# M4G8 register map
File version: 0.1
Registers are 32-bit, read-write, reset 0x0 unless marked. A register's access mark holds for its fields unless they carry their own. Offsets are from the block's base; [hi:lo] are bit positions; {n}, {i} and the like mark numbered series.

## RTC — Real Time Clock (RTC)
Base 0x400E4800
0x00 SECR 8-bit (reset mask 0x80) — RTC Sec setting register
  [6:0] SE
0x01 MINR 8-bit (reset mask 0x80) — RTC Min settging register
  [6:0] MI
0x02 HOURR 8-bit (reset mask 0xC0) — RTC Hour setting register
  [5:0] HO
0x04 DAYR 8-bit (reset mask 0xF8) — RTC Day setting register
  [2:0] WE
0x05 DATER 8-bit (reset mask 0xC0) — RTC Date setting register
  [5:0] DA
0x06 MONTHR_A 8-bit (reset mask 0xE0) — RTC Month settging register PAGE0
  [4:0] MO
0x06 MONTHR_B 8-bit (reset mask 0xFE) (RTC_MONTHR view) — RTC Month settging register PAGE0
  [0] MO0
0x07 YEARR_A 8-bit reset not defined — RTC Year setting register PAGE0
  [7:0] YE
0x07 YEARR_B 8-bit (reset mask 0xFC) (RTC_YEARR view) — RTC Leap year register PAGE1
  [1:0] LEAP
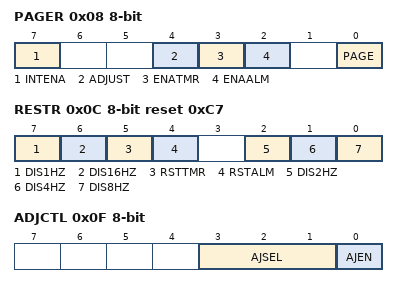
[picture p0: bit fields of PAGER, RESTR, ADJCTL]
0x08 PAGER 8-bit (reset mask 0xF3) — RTC Page register
  [7] INTENA, [4] ADJUST, [3] ENATMR, [2] ENAALM, [0] PAGE
0x0C RESTR 8-bit reset 0xC7 — RTC Reset register
  [7] DIS1HZ, [6] DIS16HZ, [5] RSTTMR, [4] RSTALM, [2] DIS2HZ, [1] DIS4HZ, [0] DIS8HZ
0x0E PROTECT 8-bit reset 0xC1 — RTC clock adjust control register
0x0F ADJCTL 8-bit — RTC protect register
  [3:1] AJSEL, [0] AJEN
0x10 ADJDAT 8-bit reset not defined — RTC clock adjust data register
0x11 ADJSIGN 8-bit (reset mask 0xFE)
  [0] ADJSIGN

## CEC — Consumer Electronics Control (CEC)
Base 0x400E8000
0x00 EN — CEC Enable Register
  [0] CECEN
0x04 ADD — CEC Logical Address Register
  [15:0] CECADD
0x08 RESET wo — CEC Software Reset Register
  [0] CECRESET
0x0C REN (reset mask 0xFFFFFFFE) — CEC Receive Enable Register
  [0] CECREN
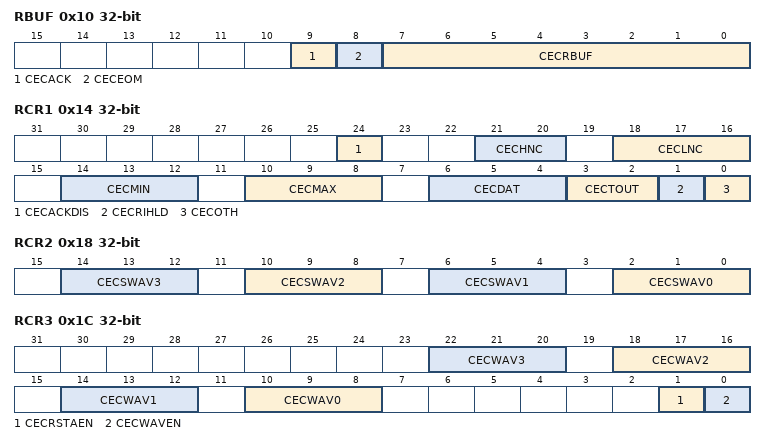
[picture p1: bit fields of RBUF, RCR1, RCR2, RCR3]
0x10 RBUF ro — CEC Receive Buffer Register
  [9] CECACK, [8] CECEOM, [7:0] CECRBUF
0x14 RCR1 — CEC Receive Control Register 1
  [24] CECACKDIS, [21:20] CECHNC, [18:16] CECLNC, [14:12] CECMIN, [10:8] CECMAX, [6:4] CECDAT, [3:2] CECTOUT, [1] CECRIHLD, [0] CECOTH
0x18 RCR2 — CEC Receive Control Register 2
  [4n+2:4n] CECSWAV{n} (n=0..3)
0x1C RCR3 — CEC Receive Control Register 3
  [4n+10:4n+8] CECWAV{n} (n=0..3), [1] CECRSTAEN, [0] CECWAVEN
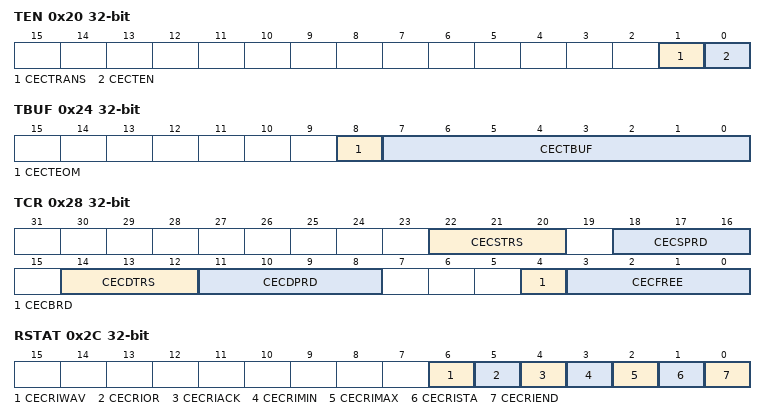
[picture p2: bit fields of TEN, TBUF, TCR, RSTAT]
0x20 TEN (reset mask 0xFFFFFFFE) — CEC Transmit Enable Register
  [1] CECTRANS ro, [0] CECTEN wo
0x24 TBUF — CEC Transmit Buffer Register
  [8] CECTEOM, [7:0] CECTBUF
0x28 TCR — CEC Transmit Control Register
  [22:20] CECSTRS, [18:16] CECSPRD, [14:12] CECDTRS, [11:8] CECDPRD, [4] CECBRD, [3:0] CECFREE
0x2C RSTAT ro — CEC Receive Interrupt Status Register
  [6] CECRIWAV, [5] CECRIOR, [4] CECRIACK, [3] CECRIMIN, [2] CECRIMAX, [1] CECRISTA, [0] CECRIEND
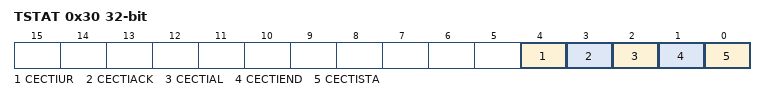
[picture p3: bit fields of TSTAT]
0x30 TSTAT ro — CEC Transmit Interrupt Status Register
  [4] CECTIUR, [3] CECTIACK, [2] CECTIAL, [1] CECTIEND, [0] CECTISTA
0x34 FSSEL — CEC sampling clock selection Register
  [0] CECCLK

## RMC — Remote Control Signal Preprocessor (RMC)
Base 0x400E8100
0x00 EN — RMC Enable Register
  [0] RMCEN
0x04 REN — RMC Receive Enable Register
  [0] RMCREN
0x08 RBUF1 ro — RMC Receive Data Buffer Register 1
  [31:0] RMCRBUF
0x0C RBUF2 ro — RMC Receive Data Buffer Register 2
  [31:0] RMCRBUF
0x10 RBUF3 ro — RMC Receive Data Buffer Register 3
  [7:0] RMCRBUF
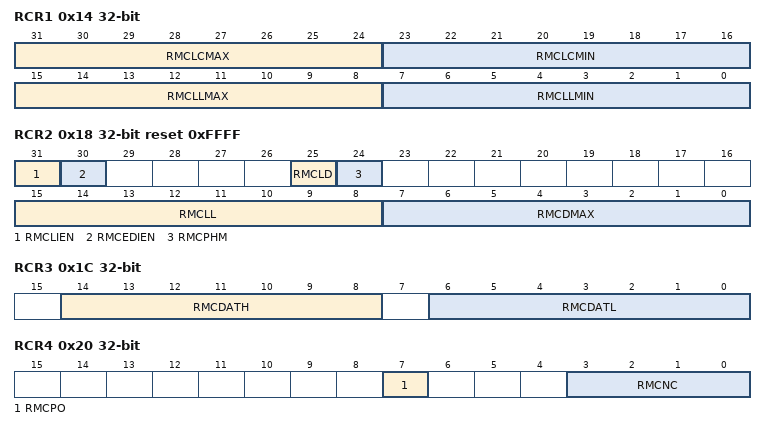
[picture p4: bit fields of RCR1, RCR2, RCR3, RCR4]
0x14 RCR1 — RMC Receive Control Register 1
  [31:24] RMCLCMAX, [23:16] RMCLCMIN, [15:8] RMCLLMAX, [7:0] RMCLLMIN
0x18 RCR2 reset 0xFFFF — RMC Receive Control Register 2
  [31] RMCLIEN, [30] RMCEDIEN, [25] RMCLD, [24] RMCPHM, [15:8] RMCLL, [7:0] RMCDMAX
0x1C RCR3 — RMC Receive Control Register 3
  [14:8] RMCDATH, [6:0] RMCDATL
0x20 RCR4 — RMC Receive Control Register 4
  [7] RMCPO, [3:0] RMCNC
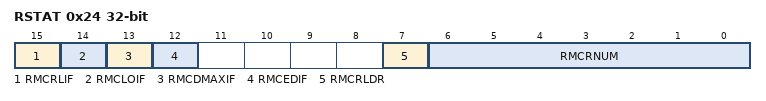
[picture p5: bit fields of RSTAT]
0x24 RSTAT ro — RMC Receive Status Register
  [15] RMCRLIF, [14] RMCLOIF, [13] RMCDMAXIF, [12] RMCEDIF, [7] RMCRLDR, [6:0] RMCRNUM
{0x24+4i} END{i} (i=1..3) — RMC Receive End Bit Number Register {i}
  [6:0] RMCEND{i}
0x34 FSSEL — RMC Frequency Selection Register
  [0] RMCCLK
